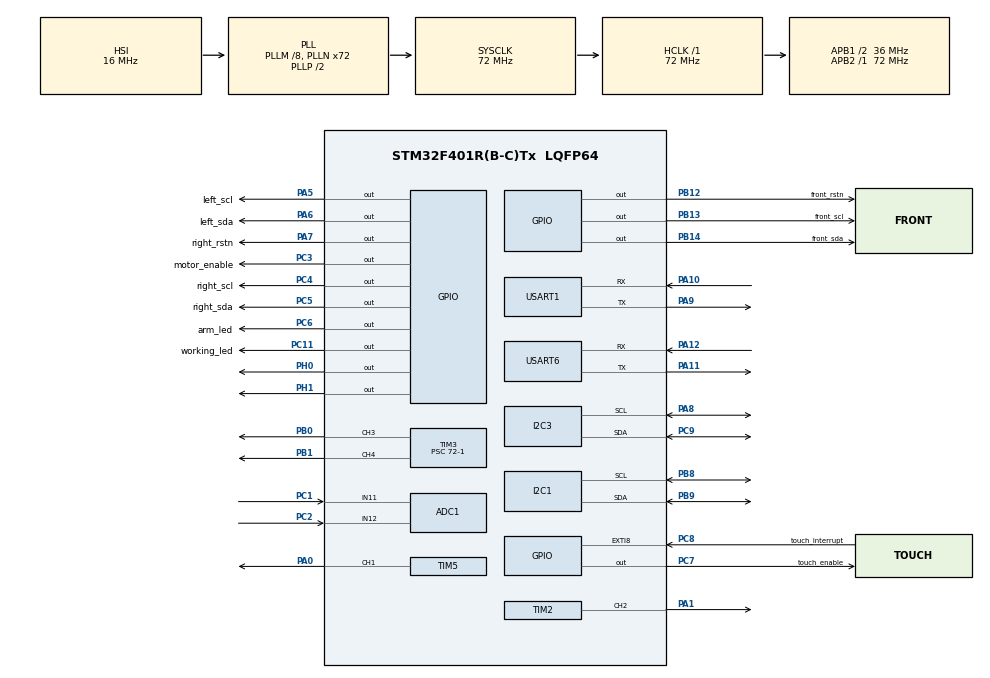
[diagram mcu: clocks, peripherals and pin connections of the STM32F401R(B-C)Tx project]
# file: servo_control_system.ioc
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ADC1.Channel-11\#ChannelRegularConversion=ADC_CHANNEL_12
ADC1.Channel-12\#ChannelRegularConversion=ADC_CHANNEL_11
ADC1.ClockPrescaler=ADC_CLOCK_SYNC_PCLK_DIV6
ADC1.ContinuousConvMode=ENABLE
ADC1.DMAContinuousRequests=ENABLE
ADC1.NbrOfConversion=2
ADC1.NbrOfConversionFlag=1
ADC1.Rank-11\#ChannelRegularConversion=1
ADC1.Rank-12\#ChannelRegularConversion=2
ADC1.SamplingTime-11\#ChannelRegularConversion=ADC_SAMPLETIME_480CYCLES
ADC1.SamplingTime-12\#ChannelRegularConversion=ADC_SAMPLETIME_480CYCLES
ADC1.ScanConvMode=ENABLE
ADC1.master=1
Dma.ADC1.6.Direction=DMA_PERIPH_TO_MEMORY
Dma.ADC1.6.FIFOMode=DMA_FIFOMODE_DISABLE
Dma.ADC1.6.Instance=DMA2_Stream0
Dma.ADC1.6.MemDataAlignment=DMA_MDATAALIGN_HALFWORD
Dma.ADC1.6.MemInc=DMA_MINC_ENABLE
Dma.ADC1.6.Mode=DMA_CIRCULAR
Dma.ADC1.6.PeriphDataAlignment=DMA_PDATAALIGN_HALFWORD
Dma.ADC1.6.PeriphInc=DMA_PINC_DISABLE
Dma.ADC1.6.Priority=DMA_PRIORITY_LOW
Dma.I2C1_RX.5.Direction=DMA_PERIPH_TO_MEMORY
Dma.I2C1_RX.5.FIFOMode=DMA_FIFOMODE_DISABLE
Dma.I2C1_RX.5.Instance=DMA1_Stream0
Dma.I2C1_RX.5.MemDataAlignment=DMA_MDATAALIGN_BYTE
Dma.I2C1_RX.5.MemInc=DMA_MINC_ENABLE
Dma.I2C1_RX.5.Mode=DMA_CIRCULAR
Dma.I2C1_RX.5.PeriphDataAlignment=DMA_PDATAALIGN_BYTE
Dma.I2C1_RX.5.PeriphInc=DMA_PINC_DISABLE
Dma.I2C1_RX.5.Priority=DMA_PRIORITY_LOW
Dma.I2C3_RX.4.Direction=DMA_PERIPH_TO_MEMORY
Dma.I2C3_RX.4.FIFOMode=DMA_FIFOMODE_DISABLE
Dma.I2C3_RX.4.Instance=DMA1_Stream1
Dma.I2C3_RX.4.MemDataAlignment=DMA_MDATAALIGN_BYTE
Dma.I2C3_RX.4.MemInc=DMA_MINC_ENABLE
Dma.I2C3_RX.4.Mode=DMA_CIRCULAR
Dma.I2C3_RX.4.PeriphDataAlignment=DMA_PDATAALIGN_BYTE
Dma.I2C3_RX.4.PeriphInc=DMA_PINC_DISABLE
Dma.I2C3_RX.4.Priority=DMA_PRIORITY_LOW
Dma.Request0=USART1_RX
Dma.Request1=USART1_TX
Dma.Request2=USART6_RX
Dma.Request3=USART6_TX
Dma.Request4=I2C3_RX
Dma.Request5=I2C1_RX
Dma.Request6=ADC1
Dma.USART1_RX.0.Direction=DMA_PERIPH_TO_MEMORY
Dma.USART1_RX.0.FIFOMode=DMA_FIFOMODE_DISABLE
Dma.USART1_RX.0.Instance=DMA2_Stream2
Dma.USART1_RX.0.MemDataAlignment=DMA_MDATAALIGN_BYTE
Dma.USART1_RX.0.MemInc=DMA_MINC_ENABLE
Dma.USART1_RX.0.Mode=DMA_CIRCULAR
Dma.USART1_RX.0.PeriphDataAlignment=DMA_PDATAALIGN_BYTE
Dma.USART1_RX.0.PeriphInc=DMA_PINC_DISABLE
Dma.USART1_RX.0.Priority=DMA_PRIORITY_LOW
Dma.USART1_TX.1.Direction=DMA_MEMORY_TO_PERIPH
Dma.USART1_TX.1.FIFOMode=DMA_FIFOMODE_DISABLE
Dma.USART1_TX.1.Instance=DMA2_Stream7
Dma.USART1_TX.1.MemDataAlignment=DMA_MDATAALIGN_BYTE
Dma.USART1_TX.1.MemInc=DMA_MINC_ENABLE
Dma.USART1_TX.1.Mode=DMA_NORMAL
Dma.USART1_TX.1.PeriphDataAlignment=DMA_PDATAALIGN_BYTE
Dma.USART1_TX.1.PeriphInc=DMA_PINC_DISABLE
Dma.USART1_TX.1.Priority=DMA_PRIORITY_LOW
Dma.USART6_RX.2.Direction=DMA_PERIPH_TO_MEMORY
Dma.USART6_RX.2.FIFOMode=DMA_FIFOMODE_DISABLE
Dma.USART6_RX.2.Instance=DMA2_Stream1
Dma.USART6_RX.2.MemDataAlignment=DMA_MDATAALIGN_BYTE
Dma.USART6_RX.2.MemInc=DMA_MINC_ENABLE
Dma.USART6_RX.2.Mode=DMA_CIRCULAR
Dma.USART6_RX.2.PeriphDataAlignment=DMA_PDATAALIGN_BYTE
Dma.USART6_RX.2.PeriphInc=DMA_PINC_DISABLE
Dma.USART6_RX.2.Priority=DMA_PRIORITY_LOW
Dma.USART6_TX.3.Direction=DMA_MEMORY_TO_PERIPH
Dma.USART6_TX.3.FIFOMode=DMA_FIFOMODE_DISABLE
Dma.USART6_TX.3.Instance=DMA2_Stream6
Dma.USART6_TX.3.MemDataAlignment=DMA_MDATAALIGN_BYTE
Dma.USART6_TX.3.MemInc=DMA_MINC_ENABLE
Dma.USART6_TX.3.Mode=DMA_NORMAL
Dma.USART6_TX.3.PeriphDataAlignment=DMA_PDATAALIGN_BYTE
Dma.USART6_TX.3.PeriphInc=DMA_PINC_DISABLE
Dma.USART6_TX.3.Priority=DMA_PRIORITY_LOW
I2C1.OwnAddress=0x22
Mcu.Family=STM32F4
Mcu.Name=STM32F401R(B-C)Tx
Mcu.Package=LQFP64
NVIC.ADC_IRQn=true\:0\:0\:false\:false\:true
NVIC.DMA1_Stream0_IRQn=true\:0\:0\:false\:false\:true
NVIC.DMA1_Stream1_IRQn=true\:0\:0\:false\:false\:true
NVIC.DMA2_Stream0_IRQn=true\:0\:0\:false\:false\:true
NVIC.DMA2_Stream1_IRQn=true\:0\:0\:false\:false\:true
NVIC.DMA2_Stream2_IRQn=true\:0\:0\:false\:false\:true
NVIC.DMA2_Stream6_IRQn=true\:0\:0\:false\:false\:true
NVIC.DMA2_Stream7_IRQn=true\:0\:0\:false\:false\:true
NVIC.EXTI9_5_IRQn=true\:0\:0\:false\:false\:true
NVIC.I2C1_ER_IRQn=true\:0\:0\:false\:false\:true
NVIC.I2C1_EV_IRQn=true\:0\:0\:false\:false\:true
NVIC.I2C3_ER_IRQn=true\:0\:0\:false\:false\:true
NVIC.I2C3_EV_IRQn=true\:0\:0\:false\:false\:true
NVIC.PriorityGroup=NVIC_PRIORITYGROUP_4
NVIC.TIM2_IRQn=true\:0\:0\:false\:false\:true
NVIC.TIM3_IRQn=true\:0\:0\:false\:false\:true
NVIC.TIM5_IRQn=true\:0\:0\:false\:false\:true
NVIC.USART1_IRQn=true\:0\:0\:false\:false\:true
NVIC.USART6_IRQn=true\:0\:0\:false\:false\:true
PA0-WKUP.Signal=S_TIM5_CH1
PA1.Signal=S_TIM2_CH2
PA10.Mode=Asynchronous
PA10.Signal=USART1_RX
PA11.Mode=Asynchronous
PA11.Signal=USART6_TX
PA12.Mode=Asynchronous
PA12.Signal=USART6_RX
PA5.GPIO_Label=left_scl
PA5.GPIO_ModeDefaultOutputPP=GPIO_MODE_OUTPUT_OD
PA5.Signal=GPIO_Output
PA6.GPIO_Label=left_sda
PA6.GPIO_ModeDefaultOutputPP=GPIO_MODE_OUTPUT_OD
PA6.Signal=GPIO_Output
PA7.GPIO_Label=right_rstn
PA7.Signal=GPIO_Output
PA8.Mode=I2C
PA8.Signal=I2C3_SCL
PA9.Mode=Asynchronous
PA9.Signal=USART1_TX
PB0.Signal=S_TIM3_CH3
PB1.Signal=S_TIM3_CH4
PB12.GPIO_Label=front_rstn
PB12.Signal=GPIO_Output
PB13.GPIO_Label=front_scl
PB13.GPIO_ModeDefaultOutputPP=GPIO_MODE_OUTPUT_OD
PB13.Signal=GPIO_Output
PB14.GPIO_Label=front_sda
PB14.GPIO_ModeDefaultOutputPP=GPIO_MODE_OUTPUT_OD
PB14.Signal=GPIO_Output
PB8.Mode=I2C
PB8.Signal=I2C1_SCL
PB9.Mode=I2C
PB9.Signal=I2C1_SDA
PC1.Signal=ADCx_IN11
PC11.GPIO_Label=working_led
PC11.Signal=GPIO_Output
PC2.Signal=ADCx_IN12
PC3.GPIO_Label=motor_enable
PC3.Signal=GPIO_Output
PC4.GPIO_Label=right_scl
PC4.GPIO_ModeDefaultOutputPP=GPIO_MODE_OUTPUT_OD
PC4.Signal=GPIO_Output
PC5.GPIO_Label=right_sda
PC5.GPIO_ModeDefaultOutputPP=GPIO_MODE_OUTPUT_OD
PC5.Signal=GPIO_Output
PC6.GPIO_Label=arm_led
PC6.Signal=GPIO_Output
PC7.GPIO_Label=touch_enable
PC7.Signal=GPIO_Output
PC8.GPIO_Label=touch_interrupt
PC8.Signal=GPXTI8
PC9.Mode=I2C
PC9.Signal=I2C3_SDA
PH0\ -\ OSC_IN.Signal=GPIO_Output
PH1\ -\ OSC_OUT.Signal=GPIO_Output
ProjectManager.HeapSize=0x200
ProjectManager.StackSize=0x400
ProjectManager.TargetToolchain=MDK-ARM V5
RCC.48MHZClocksFreq_Value=36000000
RCC.AHBFreq_Value=72000000
RCC.APB1CLKDivider=RCC_HCLK_DIV2
RCC.APB1Freq_Value=36000000
RCC.APB1TimFreq_Value=72000000
RCC.APB2Freq_Value=72000000
RCC.APB2TimFreq_Value=72000000
RCC.CortexFreq_Value=72000000
RCC.HCLKFreq_Value=72000000
RCC.HSE_VALUE=25000000
RCC.HSI_VALUE=16000000
RCC.LSE_VALUE=32768
RCC.PLLM=8
RCC.PLLN=72
RCC.SYSCLKFreq_VALUE=72000000
RCC.SYSCLKSource=RCC_SYSCLKSOURCE_PLLCLK
RCC.VCOOutputFreq_Value=144000000
SH.ADCx_IN11.0=ADC1_IN11,IN11
SH.ADCx_IN12.0=ADC1_IN12,IN12
SH.S_TIM2_CH2.0=TIM2_CH2,PWM Generation2 CH2
SH.S_TIM3_CH3.0=TIM3_CH3,PWM Generation3 CH3
SH.S_TIM3_CH4.0=TIM3_CH4,PWM Generation4 CH4
SH.S_TIM5_CH1.0=TIM5_CH1,PWM Generation1 CH1
TIM2.Channel-PWM\ Generation2\ CH2=TIM_CHANNEL_2
TIM2.Period=100-1
TIM2.Prescaler=72-1
TIM3.Channel-PWM\ Generation3\ CH3=TIM_CHANNEL_3
TIM3.Channel-PWM\ Generation4\ CH4=TIM_CHANNEL_4
TIM3.Period=100-1
TIM3.Prescaler=72-1
TIM5.Period=3000-1
TIM5.Prescaler=72-1
VP_TIM2_VS_ClockSourceINT.Mode=Internal
VP_TIM3_VS_ClockSourceINT.Mode=Internal
VP_TIM5_VS_ClockSourceINT.Mode=Internal
board=servo_control_system

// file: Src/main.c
/**
  ******************************************************************************
  * File Name          : main.c
  * Description        : Main program body
  ******************************************************************************
  *
  * COPYRIGHT(c) 2017 STMicroelectronics
  *
  * Redistribution and use in source and binary forms, with or without modification,
  * are permitted provided that the following conditions are met:
  *   1. Redistributions of source code must retain the above copyright notice,
  *      this list of conditions and the following disclaimer.
  *   2. Redistributions in binary form must reproduce the above copyright notice,
  *      this list of conditions and the following disclaimer in the documentation
  *      and/or other materials provided with the distribution.
  *   3. Neither the name of STMicroelectronics nor the names of its contributors
  *      may be used to endorse or promote products derived from this software
  *      without specific prior written permission.
  *
  * THIS SOFTWARE IS PROVIDED BY THE COPYRIGHT HOLDERS AND CONTRIBUTORS "AS IS"
  * AND ANY EXPRESS OR IMPLIED WARRANTIES, INCLUDING, BUT NOT LIMITED TO, THE
  * IMPLIED WARRANTIES OF MERCHANTABILITY AND FITNESS FOR A PARTICULAR PURPOSE ARE
  * DISCLAIMED. IN NO EVENT SHALL THE COPYRIGHT HOLDER OR CONTRIBUTORS BE LIABLE
  * FOR ANY DIRECT, INDIRECT, INCIDENTAL, SPECIAL, EXEMPLARY, OR CONSEQUENTIAL
  * DAMAGES (INCLUDING, BUT NOT LIMITED TO, PROCUREMENT OF SUBSTITUTE GOODS OR
  * SERVICES; LOSS OF USE, DATA, OR PROFITS; OR BUSINESS INTERRUPTION) HOWEVER
  * CAUSED AND ON ANY THEORY OF LIABILITY, WHETHER IN CONTRACT, STRICT LIABILITY,
  * OR TORT (INCLUDING NEGLIGENCE OR OTHERWISE) ARISING IN ANY WAY OUT OF THE USE
  * OF THIS SOFTWARE, EVEN IF ADVISED OF THE POSSIBILITY OF SUCH DAMAGE.
  *
  ******************************************************************************
  */
#include "main.h"
#include "stm32f4xx_hal.h"

ADC_HandleTypeDef hadc1;
DMA_HandleTypeDef hdma_adc1;

I2C_HandleTypeDef hi2c1;
I2C_HandleTypeDef hi2c3;
DMA_HandleTypeDef hdma_i2c1_rx;
DMA_HandleTypeDef hdma_i2c3_rx;

TIM_HandleTypeDef htim2;
TIM_HandleTypeDef htim3;
TIM_HandleTypeDef htim5;

UART_HandleTypeDef huart1;
UART_HandleTypeDef huart6;
DMA_HandleTypeDef hdma_usart1_rx;
DMA_HandleTypeDef hdma_usart1_tx;
DMA_HandleTypeDef hdma_usart6_rx;
DMA_HandleTypeDef hdma_usart6_tx;

/* USER CODE BEGIN PV */
/* Private variables ---------------------------------------------------------*/

/* USER CODE END PV */

void SystemClock_Config(void);
void Error_Handler(void);
static void MX_GPIO_Init(void);
static void MX_DMA_Init(void);
static void MX_TIM2_Init(void);
static void MX_TIM3_Init(void);
static void MX_TIM5_Init(void);
static void MX_ADC1_Init(void);
static void MX_I2C1_Init(void);
static void MX_I2C3_Init(void);
static void MX_USART1_UART_Init(void);
static void MX_USART6_UART_Init(void);

void HAL_TIM_MspPostInit(TIM_HandleTypeDef *htim);

/* USER CODE BEGIN PFP */
/* Private function prototypes -----------------------------------------------*/

/* USER CODE END PFP */

/* USER CODE BEGIN 0 */
extern  void  loop_app(void);
/* USER CODE END 0 */

int main(void)
{

  /* MCU Configuration----------------------------------------------------------*/

  /* Reset of all peripherals, Initializes the Flash interface and the Systick. */
  HAL_Init();

  /* Configure the system clock */
  SystemClock_Config();

  /* Initialize all configured peripherals */
  MX_GPIO_Init();
  MX_DMA_Init();
  MX_TIM2_Init();
  MX_TIM3_Init();
  MX_TIM5_Init();
  MX_ADC1_Init();
  MX_I2C1_Init();
  MX_I2C3_Init();
  MX_USART1_UART_Init();
  MX_USART6_UART_Init();

  /* Infinite loop */
  /* USER CODE BEGIN WHILE */

	loop_app();

  while (1)
  {
	   /*Configure GPIO pin Output Level */
     ;
     /*Configure GPIO pin Output Level */

  /* USER CODE END WHILE */

  }

}

/** System Clock Configuration
*/
void SystemClock_Config(void)
{

  RCC_OscInitTypeDef RCC_OscInitStruct;
  RCC_ClkInitTypeDef RCC_ClkInitStruct;

    /**Configure the main internal regulator output voltage
    */
  __HAL_RCC_PWR_CLK_ENABLE();

  __HAL_PWR_VOLTAGESCALING_CONFIG(PWR_REGULATOR_VOLTAGE_SCALE2);

    /**Initializes the CPU, AHB and APB busses clocks
    */
  RCC_OscInitStruct.OscillatorType = RCC_OSCILLATORTYPE_HSI;
  RCC_OscInitStruct.HSIState = RCC_HSI_ON;
  RCC_OscInitStruct.HSICalibrationValue = 16;
  RCC_OscInitStruct.PLL.PLLState = RCC_PLL_ON;
  RCC_OscInitStruct.PLL.PLLSource = RCC_PLLSOURCE_HSI;
  RCC_OscInitStruct.PLL.PLLM = 8;
  RCC_OscInitStruct.PLL.PLLN = 72;
  RCC_OscInitStruct.PLL.PLLP = RCC_PLLP_DIV2;
  RCC_OscInitStruct.PLL.PLLQ = 4;
  if (HAL_RCC_OscConfig(&RCC_OscInitStruct) != HAL_OK)
  {
    Error_Handler();
  }

    /**Initializes the CPU, AHB and APB busses clocks
    */
  RCC_ClkInitStruct.ClockType = RCC_CLOCKTYPE_HCLK|RCC_CLOCKTYPE_SYSCLK
                              |RCC_CLOCKTYPE_PCLK1|RCC_CLOCKTYPE_PCLK2;
  RCC_ClkInitStruct.SYSCLKSource = RCC_SYSCLKSOURCE_PLLCLK;
  RCC_ClkInitStruct.AHBCLKDivider = RCC_SYSCLK_DIV1;
  RCC_ClkInitStruct.APB1CLKDivider = RCC_HCLK_DIV2;
  RCC_ClkInitStruct.APB2CLKDivider = RCC_HCLK_DIV1;

  if (HAL_RCC_ClockConfig(&RCC_ClkInitStruct, FLASH_LATENCY_2) != HAL_OK)
  {
    Error_Handler();
  }

    /**Configure the Systick interrupt time
    */
  HAL_SYSTICK_Config(HAL_RCC_GetHCLKFreq()/1000);

    /**Configure the Systick
    */
  HAL_SYSTICK_CLKSourceConfig(SYSTICK_CLKSOURCE_HCLK);

  /* SysTick_IRQn interrupt configuration */
  HAL_NVIC_SetPriority(SysTick_IRQn, 0, 0);
}

/* ADC1 init function */
static void MX_ADC1_Init(void)
{

  ADC_ChannelConfTypeDef sConfig;

    /**Configure the global features of the ADC (Clock, Resolution, Data Alignment and number of conversion)
    */
  hadc1.Instance = ADC1;
  hadc1.Init.ClockPrescaler = ADC_CLOCK_SYNC_PCLK_DIV6;
  hadc1.Init.Resolution = ADC_RESOLUTION_12B;
  hadc1.Init.ScanConvMode = ENABLE;
  hadc1.Init.ContinuousConvMode = ENABLE;
  hadc1.Init.DiscontinuousConvMode = DISABLE;
  hadc1.Init.ExternalTrigConvEdge = ADC_EXTERNALTRIGCONVEDGE_NONE;
  hadc1.Init.ExternalTrigConv = ADC_SOFTWARE_START;
  hadc1.Init.DataAlign = ADC_DATAALIGN_RIGHT;
  hadc1.Init.NbrOfConversion = 2;
  hadc1.Init.DMAContinuousRequests = ENABLE;
  hadc1.Init.EOCSelection = ADC_EOC_SINGLE_CONV;
  if (HAL_ADC_Init(&hadc1) != HAL_OK)
  {
    Error_Handler();
  }

    /**Configure for the selected ADC regular channel its corresponding rank in the sequencer and its sample time.
    */
  sConfig.Channel = ADC_CHANNEL_12;
  sConfig.Rank = 1;
  sConfig.SamplingTime = ADC_SAMPLETIME_480CYCLES;
  if (HAL_ADC_ConfigChannel(&hadc1, &sConfig) != HAL_OK)
  {
    Error_Handler();
  }

    /**Configure for the selected ADC regular channel its corresponding rank in the sequencer and its sample time.
    */
  sConfig.Channel = ADC_CHANNEL_11;
  sConfig.Rank = 2;
  if (HAL_ADC_ConfigChannel(&hadc1, &sConfig) != HAL_OK)
  {
    Error_Handler();
  }

}

/* I2C1 init function */
static void MX_I2C1_Init(void)
{

  hi2c1.Instance = I2C1;
  hi2c1.Init.ClockSpeed = 100000;
  hi2c1.Init.DutyCycle = I2C_DUTYCYCLE_2;
  hi2c1.Init.OwnAddress1 = 68;
  hi2c1.Init.AddressingMode = I2C_ADDRESSINGMODE_7BIT;
  hi2c1.Init.DualAddressMode = I2C_DUALADDRESS_DISABLE;
  hi2c1.Init.OwnAddress2 = 0;
  hi2c1.Init.GeneralCallMode = I2C_GENERALCALL_DISABLE;
  hi2c1.Init.NoStretchMode = I2C_NOSTRETCH_DISABLE;
  if (HAL_I2C_Init(&hi2c1) != HAL_OK)
  {
    Error_Handler();
  }

}

/* I2C3 init function */
static void MX_I2C3_Init(void)
{

  hi2c3.Instance = I2C3;
  hi2c3.Init.ClockSpeed = 100000;
  hi2c3.Init.DutyCycle = I2C_DUTYCYCLE_2;
  hi2c3.Init.OwnAddress1 = 0;
  hi2c3.Init.AddressingMode = I2C_ADDRESSINGMODE_7BIT;
  hi2c3.Init.DualAddressMode = I2C_DUALADDRESS_DISABLE;
  hi2c3.Init.OwnAddress2 = 0;
  hi2c3.Init.GeneralCallMode = I2C_GENERALCALL_DISABLE;
  hi2c3.Init.NoStretchMode = I2C_NOSTRETCH_DISABLE;
  if (HAL_I2C_Init(&hi2c3) != HAL_OK)
  {
    Error_Handler();
  }

}

/* TIM2 init function */
static void MX_TIM2_Init(void)
{

  TIM_ClockConfigTypeDef sClockSourceConfig;
  TIM_MasterConfigTypeDef sMasterConfig;
  TIM_OC_InitTypeDef sConfigOC;

  htim2.Instance = TIM2;
  htim2.Init.Prescaler = 72-1;
  htim2.Init.CounterMode = TIM_COUNTERMODE_UP;
  htim2.Init.Period = 100-1;
  htim2.Init.ClockDivision = TIM_CLOCKDIVISION_DIV1;
  if (HAL_TIM_Base_Init(&htim2) != HAL_OK)
  {
    Error_Handler();
  }

  sClockSourceConfig.ClockSource = TIM_CLOCKSOURCE_INTERNAL;
  if (HAL_TIM_ConfigClockSource(&htim2, &sClockSourceConfig) != HAL_OK)
  {
    Error_Handler();
  }

  if (HAL_TIM_PWM_Init(&htim2) != HAL_OK)
  {
    Error_Handler();
  }

  sMasterConfig.MasterOutputTrigger = TIM_TRGO_RESET;
  sMasterConfig.MasterSlaveMode = TIM_MASTERSLAVEMODE_DISABLE;
  if (HAL_TIMEx_MasterConfigSynchronization(&htim2, &sMasterConfig) != HAL_OK)
  {
    Error_Handler();
  }

  sConfigOC.OCMode = TIM_OCMODE_PWM1;
  sConfigOC.Pulse = 0;
  sConfigOC.OCPolarity = TIM_OCPOLARITY_HIGH;
  sConfigOC.OCFastMode = TIM_OCFAST_DISABLE;
  if (HAL_TIM_PWM_ConfigChannel(&htim2, &sConfigOC, TIM_CHANNEL_2) != HAL_OK)
  {
    Error_Handler();
  }

  HAL_TIM_MspPostInit(&htim2);

}

/* TIM3 init function */
static void MX_TIM3_Init(void)
{

  TIM_ClockConfigTypeDef sClockSourceConfig;
  TIM_MasterConfigTypeDef sMasterConfig;
  TIM_OC_InitTypeDef sConfigOC;

  htim3.Instance = TIM3;
  htim3.Init.Prescaler = 72-1;
  htim3.Init.CounterMode = TIM_COUNTERMODE_UP;
  htim3.Init.Period = 100-1;
  htim3.Init.ClockDivision = TIM_CLOCKDIVISION_DIV1;
  if (HAL_TIM_Base_Init(&htim3) != HAL_OK)
  {
    Error_Handler();
  }

  sClockSourceConfig.ClockSource = TIM_CLOCKSOURCE_INTERNAL;
  if (HAL_TIM_ConfigClockSource(&htim3, &sClockSourceConfig) != HAL_OK)
  {
    Error_Handler();
  }

  if (HAL_TIM_PWM_Init(&htim3) != HAL_OK)
  {
    Error_Handler();
  }

  sMasterConfig.MasterOutputTrigger = TIM_TRGO_RESET;
  sMasterConfig.MasterSlaveMode = TIM_MASTERSLAVEMODE_DISABLE;
  if (HAL_TIMEx_MasterConfigSynchronization(&htim3, &sMasterConfig) != HAL_OK)
  {
    Error_Handler();
  }

  sConfigOC.OCMode = TIM_OCMODE_PWM1;
  sConfigOC.Pulse = 0;
  sConfigOC.OCPolarity = TIM_OCPOLARITY_HIGH;
  sConfigOC.OCFastMode = TIM_OCFAST_DISABLE;
  if (HAL_TIM_PWM_ConfigChannel(&htim3, &sConfigOC, TIM_CHANNEL_3) != HAL_OK)
  {
    Error_Handler();
  }

  if (HAL_TIM_PWM_ConfigChannel(&htim3, &sConfigOC, TIM_CHANNEL_4) != HAL_OK)
  {
    Error_Handler();
  }

  HAL_TIM_MspPostInit(&htim3);

}

/* TIM5 init function */
static void MX_TIM5_Init(void)
{

  TIM_ClockConfigTypeDef sClockSourceConfig;
  TIM_MasterConfigTypeDef sMasterConfig;
  TIM_OC_InitTypeDef sConfigOC;

  htim5.Instance = TIM5;
  htim5.Init.Prescaler = 72-1;
  htim5.Init.CounterMode = TIM_COUNTERMODE_UP;
  htim5.Init.Period = 3000-1;
  htim5.Init.ClockDivision = TIM_CLOCKDIVISION_DIV1;
  if (HAL_TIM_Base_Init(&htim5) != HAL_OK)
  {
    Error_Handler();
  }

  sClockSourceConfig.ClockSource = TIM_CLOCKSOURCE_INTERNAL;
  if (HAL_TIM_ConfigClockSource(&htim5, &sClockSourceConfig) != HAL_OK)
  {
    Error_Handler();
  }

  if (HAL_TIM_PWM_Init(&htim5) != HAL_OK)
  {
    Error_Handler();
  }

  sMasterConfig.MasterOutputTrigger = TIM_TRGO_RESET;
  sMasterConfig.MasterSlaveMode = TIM_MASTERSLAVEMODE_DISABLE;
  if (HAL_TIMEx_MasterConfigSynchronization(&htim5, &sMasterConfig) != HAL_OK)
  {
    Error_Handler();
  }

  sConfigOC.OCMode = TIM_OCMODE_PWM1;
  sConfigOC.Pulse = 0;
  sConfigOC.OCPolarity = TIM_OCPOLARITY_HIGH;
  sConfigOC.OCFastMode = TIM_OCFAST_DISABLE;
  if (HAL_TIM_PWM_ConfigChannel(&htim5, &sConfigOC, TIM_CHANNEL_1) != HAL_OK)
  {
    Error_Handler();
  }

  HAL_TIM_MspPostInit(&htim5);

}

/* USART1 init function */
static void MX_USART1_UART_Init(void)
{

  huart1.Instance = USART1;
  huart1.Init.BaudRate = 115200;
  huart1.Init.WordLength = UART_WORDLENGTH_8B;
  huart1.Init.StopBits = UART_STOPBITS_1;
  huart1.Init.Parity = UART_PARITY_NONE;
  huart1.Init.Mode = UART_MODE_TX_RX;
  huart1.Init.HwFlowCtl = UART_HWCONTROL_NONE;
  huart1.Init.OverSampling = UART_OVERSAMPLING_16;
  if (HAL_UART_Init(&huart1) != HAL_OK)
  {
    Error_Handler();
  }

}

/* USART6 init function */
static void MX_USART6_UART_Init(void)
{

  huart6.Instance = USART6;
  huart6.Init.BaudRate = 115200;
  huart6.Init.WordLength = UART_WORDLENGTH_8B;
  huart6.Init.StopBits = UART_STOPBITS_1;
  huart6.Init.Parity = UART_PARITY_NONE;
  huart6.Init.Mode = UART_MODE_TX_RX;
  huart6.Init.HwFlowCtl = UART_HWCONTROL_NONE;
  huart6.Init.OverSampling = UART_OVERSAMPLING_16;
  if (HAL_UART_Init(&huart6) != HAL_OK)
  {
    Error_Handler();
  }

}

static void MX_DMA_Init(void)
{
  /* DMA controller clock enable */
  __HAL_RCC_DMA2_CLK_ENABLE();
  __HAL_RCC_DMA1_CLK_ENABLE();

  /* DMA interrupt init */
  /* DMA1_Stream0_IRQn interrupt configuration */
  HAL_NVIC_SetPriority(DMA1_Stream0_IRQn, 0, 0);
  HAL_NVIC_EnableIRQ(DMA1_Stream0_IRQn);
  /* DMA1_Stream1_IRQn interrupt configuration */
  HAL_NVIC_SetPriority(DMA1_Stream1_IRQn, 0, 0);
  HAL_NVIC_EnableIRQ(DMA1_Stream1_IRQn);
  /* DMA2_Stream0_IRQn interrupt configuration */
  HAL_NVIC_SetPriority(DMA2_Stream0_IRQn, 0, 0);
  HAL_NVIC_EnableIRQ(DMA2_Stream0_IRQn);
  /* DMA2_Stream1_IRQn interrupt configuration */
  HAL_NVIC_SetPriority(DMA2_Stream1_IRQn, 0, 0);
  HAL_NVIC_EnableIRQ(DMA2_Stream1_IRQn);
  /* DMA2_Stream2_IRQn interrupt configuration */
  HAL_NVIC_SetPriority(DMA2_Stream2_IRQn, 0, 0);
  HAL_NVIC_EnableIRQ(DMA2_Stream2_IRQn);
  /* DMA2_Stream6_IRQn interrupt configuration */
  HAL_NVIC_SetPriority(DMA2_Stream6_IRQn, 0, 0);
  HAL_NVIC_EnableIRQ(DMA2_Stream6_IRQn);
  /* DMA2_Stream7_IRQn interrupt configuration */
  HAL_NVIC_SetPriority(DMA2_Stream7_IRQn, 0, 0);
  HAL_NVIC_EnableIRQ(DMA2_Stream7_IRQn);

}

/** Configure pins as
        * Analog
        * Input
        * Output
        * EVENT_OUT
        * EXTI
*/
static void MX_GPIO_Init(void)
{

  GPIO_InitTypeDef GPIO_InitStruct;

  /* GPIO Ports Clock Enable */
  __HAL_RCC_GPIOH_CLK_ENABLE();
  __HAL_RCC_GPIOC_CLK_ENABLE();
  __HAL_RCC_GPIOA_CLK_ENABLE();
  __HAL_RCC_GPIOB_CLK_ENABLE();

  /*Configure GPIO pin Output Level */
  HAL_GPIO_WritePin(GPIOH, GPIO_PIN_0|GPIO_PIN_1, GPIO_PIN_RESET);

  /*Configure GPIO pin Output Level */
  HAL_GPIO_WritePin(GPIOC, motor_enable_Pin|right_scl_Pin|right_sda_Pin|arm_led_Pin
                          |touch_enable_Pin|working_led_Pin, GPIO_PIN_RESET);

  /*Configure GPIO pin Output Level */
  HAL_GPIO_WritePin(GPIOA, left_scl_Pin|left_sda_Pin|right_rstn_Pin, GPIO_PIN_RESET);

  /*Configure GPIO pin Output Level */
  HAL_GPIO_WritePin(GPIOB, front_rstn_Pin|front_scl_Pin|front_sda_Pin, GPIO_PIN_RESET);

  /*Configure GPIO pins : PH0 PH1 */
  GPIO_InitStruct.Pin = GPIO_PIN_0|GPIO_PIN_1;
  GPIO_InitStruct.Mode = GPIO_MODE_OUTPUT_PP;
  GPIO_InitStruct.Pull = GPIO_NOPULL;
  GPIO_InitStruct.Speed = GPIO_SPEED_FREQ_LOW;
  HAL_GPIO_Init(GPIOH, &GPIO_InitStruct);

  /*Configure GPIO pins : motor_enable_Pin arm_led_Pin touch_enable_Pin working_led_Pin */
  GPIO_InitStruct.Pin = motor_enable_Pin|arm_led_Pin|touch_enable_Pin|working_led_Pin;
  GPIO_InitStruct.Mode = GPIO_MODE_OUTPUT_PP;
  GPIO_InitStruct.Pull = GPIO_NOPULL;
  GPIO_InitStruct.Speed = GPIO_SPEED_FREQ_LOW;
  HAL_GPIO_Init(GPIOC, &GPIO_InitStruct);

  /*Configure GPIO pins : left_scl_Pin left_sda_Pin */
  GPIO_InitStruct.Pin = left_scl_Pin|left_sda_Pin;
  GPIO_InitStruct.Mode = GPIO_MODE_OUTPUT_OD;
  GPIO_InitStruct.Pull = GPIO_NOPULL;
  GPIO_InitStruct.Speed = GPIO_SPEED_FREQ_LOW;
  HAL_GPIO_Init(GPIOA, &GPIO_InitStruct);

  /*Configure GPIO pin : right_rstn_Pin */
  GPIO_InitStruct.Pin = right_rstn_Pin;
  GPIO_InitStruct.Mode = GPIO_MODE_OUTPUT_PP;
  GPIO_InitStruct.Pull = GPIO_NOPULL;
  GPIO_InitStruct.Speed = GPIO_SPEED_FREQ_LOW;
  HAL_GPIO_Init(right_rstn_GPIO_Port, &GPIO_InitStruct);

  /*Configure GPIO pins : right_scl_Pin right_sda_Pin */
  GPIO_InitStruct.Pin = right_scl_Pin|right_sda_Pin;
  GPIO_InitStruct.Mode = GPIO_MODE_OUTPUT_OD;
  GPIO_InitStruct.Pull = GPIO_NOPULL;
  GPIO_InitStruct.Speed = GPIO_SPEED_FREQ_LOW;
  HAL_GPIO_Init(GPIOC, &GPIO_InitStruct);

  /*Configure GPIO pin : front_rstn_Pin */
  GPIO_InitStruct.Pin = front_rstn_Pin;
  GPIO_InitStruct.Mode = GPIO_MODE_OUTPUT_PP;
  GPIO_InitStruct.Pull = GPIO_NOPULL;
  GPIO_InitStruct.Speed = GPIO_SPEED_FREQ_LOW;
  HAL_GPIO_Init(front_rstn_GPIO_Port, &GPIO_InitStruct);

  /*Configure GPIO pins : front_scl_Pin front_sda_Pin */
  GPIO_InitStruct.Pin = front_scl_Pin|front_sda_Pin;
  GPIO_InitStruct.Mode = GPIO_MODE_OUTPUT_OD;
  GPIO_InitStruct.Pull = GPIO_NOPULL;
  GPIO_InitStruct.Speed = GPIO_SPEED_FREQ_LOW;
  HAL_GPIO_Init(GPIOB, &GPIO_InitStruct);

  /*Configure GPIO pin : touch_interrupt_Pin */
  GPIO_InitStruct.Pin = touch_interrupt_Pin;
  GPIO_InitStruct.Mode = GPIO_MODE_IT_RISING;
  GPIO_InitStruct.Pull = GPIO_NOPULL;
  HAL_GPIO_Init(touch_interrupt_GPIO_Port, &GPIO_InitStruct);

  /* EXTI interrupt init*/
  HAL_NVIC_SetPriority(EXTI9_5_IRQn, 0, 0);
  HAL_NVIC_EnableIRQ(EXTI9_5_IRQn);

}

void Error_Handler(void)
{
  while(1)
  {
  }
}

/************************ (C) COPYRIGHT STMicroelectronics *****END OF FILE****/
